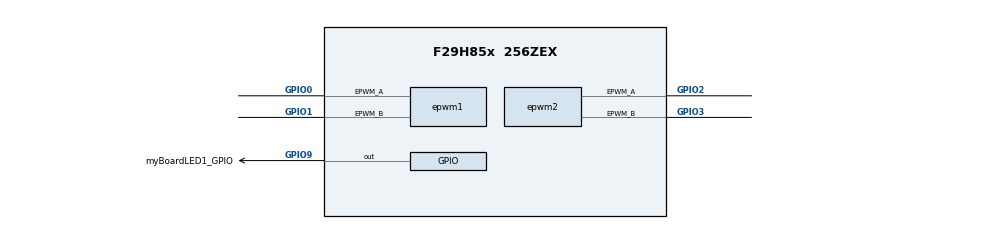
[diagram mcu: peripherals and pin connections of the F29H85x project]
/**
 * @cliArgs --device "F29H85x" --package "256ZEX" --part "F29H85x_256ZEX" --context "CPU1" --product "MCU_SDK_F29H85x@1.00.00.00"
 * @versions {"tool":"1.22.0+3877"}
 */

const divider15       = system.clockTree["PLL_REFDIV"];
divider15.divideValue = 1;

const multiplier1         = system.clockTree["PLL_IMULT"];
multiplier1.multiplyValue = 40;

const mux7       = system.clockTree["OSCCLKSRCSEL"];
mux7.inputSelect = "INTOSC2";

/**
 * Import the modules used in this configuration.
 */
const adc              = scripting.addModule("/driverlib/adc.js", {}, false);
const adc1             = adc.addInstance();
const analog           = scripting.addModule("/driverlib/analog.js", {}, false);
const analog1          = analog.addInstance();
const asysctl          = scripting.addModule("/driverlib/asysctl.js");
const cputimer         = scripting.addModule("/driverlib/cputimer.js", {}, false);
const cputimer1        = cputimer.addInstance();
const epwm             = scripting.addModule("/driverlib/epwm.js", {}, false);
const epwm1            = epwm.addInstance();
const epwm2            = epwm.addInstance();
const gpio             = scripting.addModule("/driverlib/gpio.js", {}, false);
const gpio1            = gpio.addInstance();
const inputxbar_input  = scripting.addModule("/driverlib/inputxbar_input.js", {}, false);
const inputxbar_input1 = inputxbar_input.addInstance();
const rtdma1           = scripting.addModule("/driverlib/rtdma1.js", {}, false);
const rtdma11          = rtdma1.addInstance();

/**
 * Write custom configuration values to the imported modules.
 */
adc1.$name                          = "myADC0";
adc1.adcClockPrescaler              = "ADC_CLK_DIV_4_0";
adc1.enabledSOCs                    = ["ADC_SOC_NUMBER0"];
adc1.soc0Trigger                    = "ADC_TRIGGER_EPWM2_SOCA";
adc1.interruptPulseMode             = "ADC_PULSE_END_OF_CONV";
adc1.enabledInts                    = ["ADC_INT_NUMBER1"];
adc1.enableInterrupt1               = true;
adc1.enableInterrupt1ContinuousMode = true;
adc1.periphClock.$name              = "driverlib_perClock0";
adc1.periphConfig.$name             = "driverlib_perConfig0";

analog1.$name                                = "myANALOGPinMux0";
adc1.analog                                  = analog1;
analog1.useCase                              = "CUSTOM";
analog1.useInterfacePins                     = ["A0/C24/DACA_OUT"];

asysctl.analogReferenceAB  = "INTERNAL_3_3_V";
asysctl.analogReferenceCDE = "INTERNAL_3_3_V";

cputimer1.$name             = "myCPUTIMER0";
cputimer1.timerPeriod       = 4294967295;
cputimer1.periphClock.$name = "driverlib_perClock1";

epwm1.$name                                                      = "myEPWM0";
epwm1.epwmTimebase_counterMode                                   = "EPWM_COUNTER_MODE_UP_DOWN";
epwm1.epwmActionQualifier_EPWM_AQ_OUTPUT_A_ON_TIMEBASE_UP_CMPA   = "EPWM_AQ_OUTPUT_HIGH";
epwm1.epwmActionQualifier_EPWM_AQ_OUTPUT_A_ON_TIMEBASE_DOWN_CMPA = "EPWM_AQ_OUTPUT_LOW";
epwm1.epwmActionQualifier_EPWM_AQ_OUTPUT_A_shadowMode            = true;
epwm1.epwmTimebase_syncOutPulseMode                              = ["EPWM_SYNC_OUT_PULSE_ON_CNTR_ZERO"];
epwm1.epwmTimebase_hsClockDiv                                    = "EPWM_HSCLOCK_DIVIDER_1";
epwm1.epwmTimebase_period                                        = 25000;
epwm1.epwmCounterCompare_cmpA                                    = 18750;
epwm1.epwm.$assign                                               = "EPWM1";
epwm1.epwm.epwm_aPin.$assign                                     = "GPIO0";
epwm1.epwm.epwm_bPin.$assign                                     = "GPIO1";
epwm1.periphClock.$name                                          = "driverlib_perClock3";
epwm1.periphConfig.$name                                         = "driverlib_perConfig2";

epwm2.$name                                             = "myEPWM1";
epwm2.epwmEventTrigger_EPWM_SOC_A_triggerEnable         = true;
epwm2.epwmEventTrigger_EPWM_SOC_A_triggerSource         = "EPWM_SOC_TBCTR_PERIOD";
epwm2.epwmEventTrigger_EPWM_SOC_A_triggerEventPrescalar = "1";
epwm2.epwmTimebase_syncOutPulseMode                     = ["EPWM_SYNC_OUT_PULSE_ON_CNTR_ZERO"];
epwm2.epwmTimebase_period                               = 1999;
epwm2.epwm.$assign                                      = "EPWM2";
epwm2.epwm.epwm_aPin.$assign                            = "GPIO2";
epwm2.epwm.epwm_bPin.$assign                            = "GPIO3";
epwm2.periphClock.$name                                 = "driverlib_perClock4";
epwm2.periphConfig.$name                                = "driverlib_perConfig3";

gpio1.$name           = "myBoardLED1_GPIO";
gpio1.direction       = "GPIO_DIR_MODE_OUT";
gpio1.gpioPin.$assign = "GPIO9";

inputxbar_input1.$name          = "myINPUTXBARINPUT0";
inputxbar_input1.inputxbarInput = "XBAR_INPUT7";

rtdma1.emulationMode              = "DMA_EMULATION_FREE_RUN";
rtdma1.periphClock.$name  = "driverlib_perClock2";
rtdma1.periphConfig.$name = "driverlib_perConfig1";

rtdma11.$name                      = "myRTDMA0";
rtdma11.enableTriggers             = true;
rtdma11.triggerSource              = "DMA_TRIGGER_ADCA1";
rtdma11.useInterrupts              = true;
rtdma11.registerInterrupts         = true;
rtdma11.enableInterrupts           = true;
rtdma11.continuousModeConfig       = "DMA_CFG_CONTINUOUS_ENABLE";
rtdma11.srcAddressInputMode        = "VARIABLE";
rtdma11.srcAddressVariable         = "AdcAddr";
rtdma11.destAddressInputMode       = "VARIABLE";
rtdma11.destAddressVariable        = "AdcRawBufAddr";
rtdma11.transferSize               = 50;
rtdma11.destTransferStep           = 1;
rtdma11.startChannel               = true;
rtdma11.srcWrapSize                = 50;
rtdma11.destWrapSize               = 50;
rtdma11.rtdma1Int.interruptHandler = "dma1_Ch1ISR";
